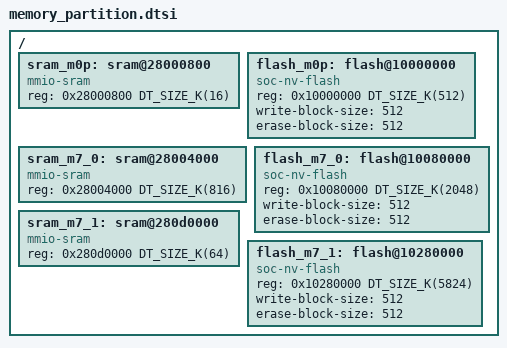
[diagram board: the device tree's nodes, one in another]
/*
 * Copyright (c) 2025 Infineon Technologies AG,
 * or an affiliate of Infineon Technologies AG.
 *
 * SPDX-License-Identifier: Apache-2.0
 */
/ {
	sram_m0p: sram@28000800 {
		compatible = "mmio-sram";
		reg = <0x28000800 DT_SIZE_K(16)>;
	};

	flash_m0p: flash@10000000 {
		compatible = "soc-nv-flash";
		reg = <0x10000000 DT_SIZE_K(512)>;
		write-block-size = <512>;
		erase-block-size = <512>;
	};

	sram_m7_0: sram@28004000 {
		compatible = "mmio-sram";
		reg = <0x28004000 DT_SIZE_K(816)>;
	};

	flash_m7_0: flash@10080000 {
		compatible = "soc-nv-flash";
		reg = <0x10080000 DT_SIZE_K(2048)>;
		write-block-size = <512>;
		erase-block-size = <512>;
	};

	sram_m7_1: sram@280d0000 {
		compatible = "mmio-sram";
		reg = <0x280d0000 DT_SIZE_K(64)>;
	};

	flash_m7_1: flash@10280000 {
		compatible = "soc-nv-flash";
		reg = <0x10280000 DT_SIZE_K(5824)>;
		write-block-size = <512>;
		erase-block-size = <512>;
	};
};
